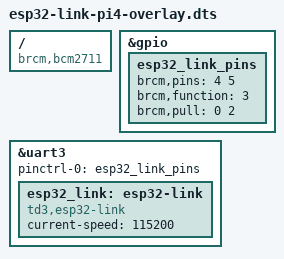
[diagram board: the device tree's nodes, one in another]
/dts-v1/;
/plugin/;

/ {
	compatible = "brcm,bcm2711";

	/* Grupo de pinctrl propio: GPIO4/GPIO5 en ALT4 (TXD3/RXD3), sin
	 * depender del pinctrl implicito del arbol base ni del overlay
	 * oficial "uart3" de la Raspberry Pi Foundation. */
	fragment@0 {
		target = <&gpio>;
		__overlay__ {
			esp32_link_pins: esp32_link_pins {
				brcm,pins = <4 5>;
				brcm,function = <3>; /* ALT4: GPIO4=TXD3, GPIO5=RXD3 */
				brcm,pull = <0 2>;   /* TX sin pull, RX con pull-up */
			};
		};
	};

	fragment@1 {
		target = <&uart3>;
		__overlay__ {
			pinctrl-names = "default";
			pinctrl-0 = <&esp32_link_pins>;
			status = "okay";

			esp32_link: esp32-link {
				compatible = "td3,esp32-link";
				current-speed = <115200>;
				status = "okay";
			};
		};
	};
};
